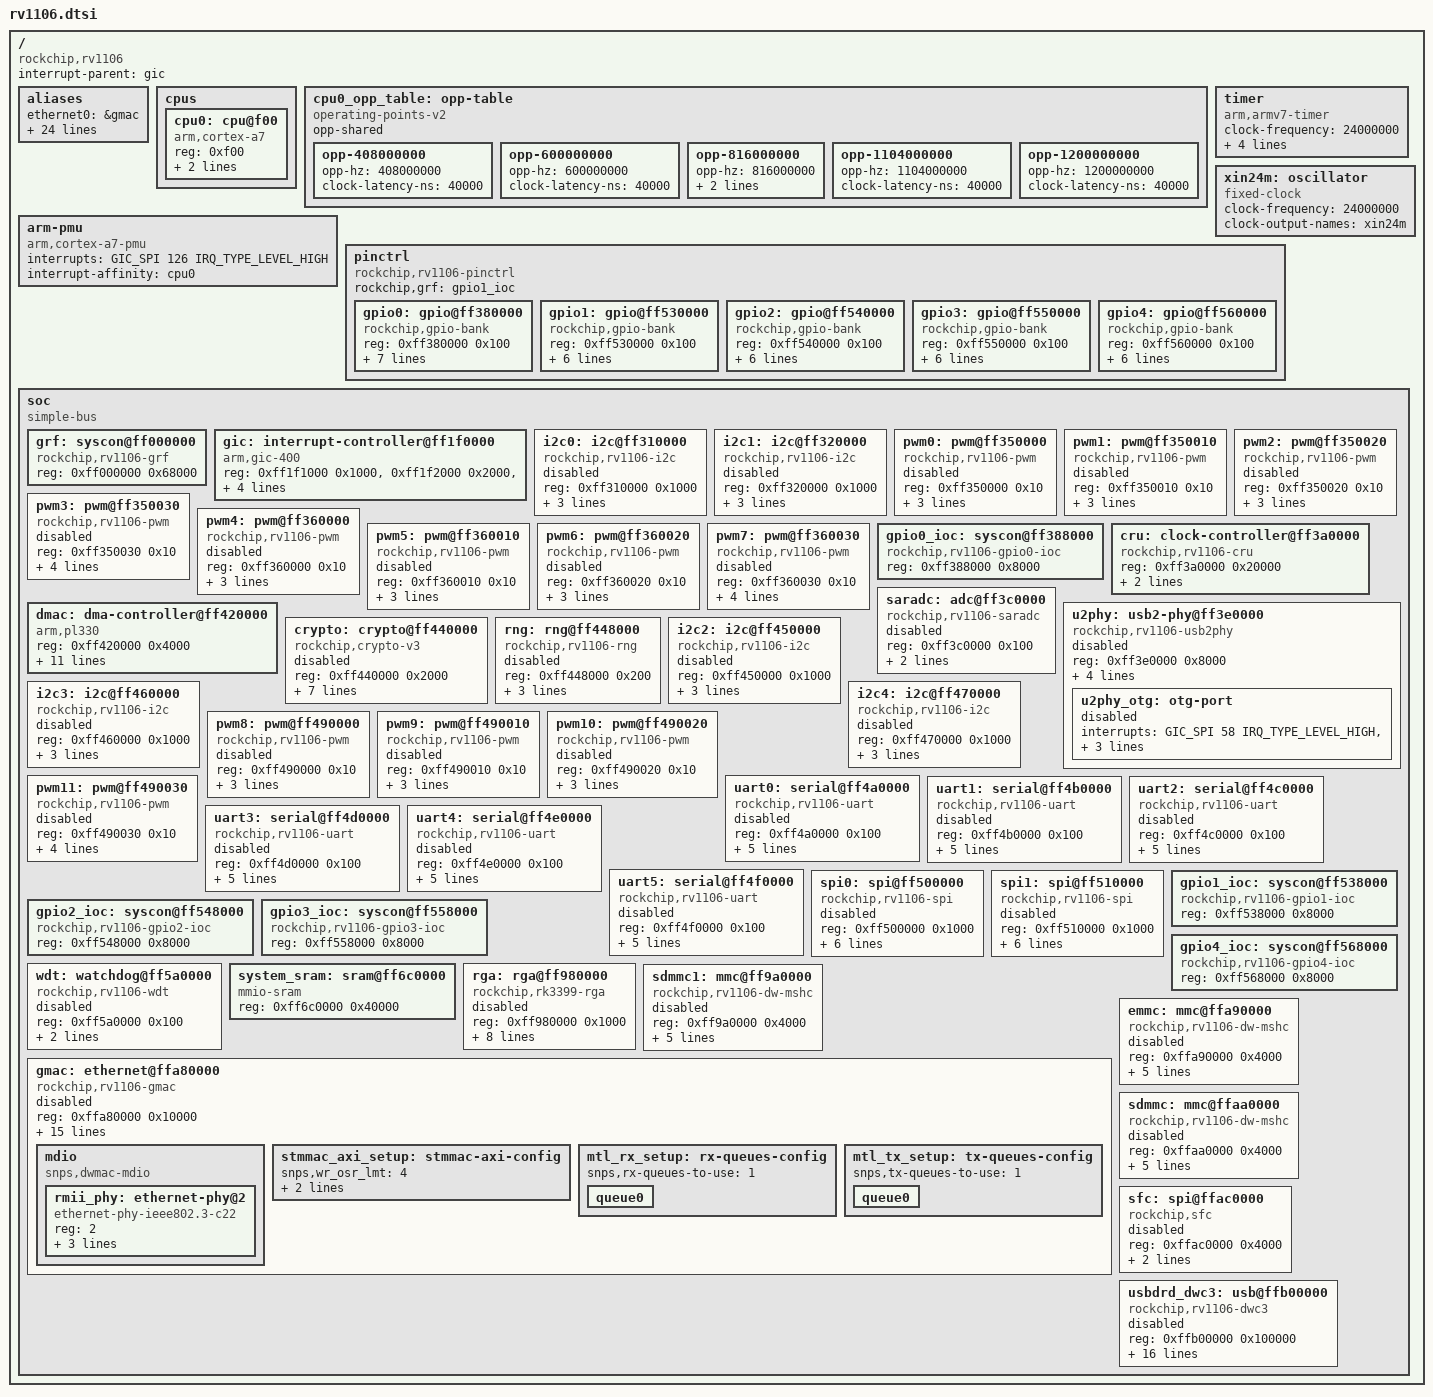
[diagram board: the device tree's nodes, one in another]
// SPDX-License-Identifier: (GPL-2.0+ OR MIT)
/*
 * Copyright (c) 2022 Rockchip Electronics Co., Ltd.
 */

#include <dt-bindings/clock/rockchip,rv1106-cru.h>
#include <dt-bindings/reset/rockchip,rv1106-cru.h>
#include <dt-bindings/gpio/gpio.h>
#include <dt-bindings/interrupt-controller/arm-gic.h>
#include <dt-bindings/interrupt-controller/irq.h>
#include <dt-bindings/pinctrl/rockchip.h>

/ {
	#address-cells = <1>;
	#size-cells = <1>;

	compatible = "rockchip,rv1106";

	interrupt-parent = <&gic>;

	aliases {
		ethernet0 = &gmac;
		gpio0 = &gpio0;
		gpio1 = &gpio1;
		gpio2 = &gpio2;
		gpio3 = &gpio3;
		gpio4 = &gpio4;
		i2c0 = &i2c0;
		i2c1 = &i2c1;
		i2c2 = &i2c2;
		i2c3 = &i2c3;
		i2c4 = &i2c4;
		pwm0 = &pwm0;
		pwm1 = &pwm1;
		pwm2 = &pwm2;
		pwm3 = &pwm3;
		pwm4 = &pwm4;
		pwm5 = &pwm5;
		pwm6 = &pwm6;
		pwm7 = &pwm7;
		pwm8 = &pwm8;
		pwm9 = &pwm9;
		pwm10 = &pwm10;
		pwm11 = &pwm11;
		spi0 = &spi0;
		spi1 = &spi1;
	};

	cpus {
		#address-cells = <1>;
		#size-cells = <0>;

		cpu0: cpu@f00 {
			device_type = "cpu";
			compatible = "arm,cortex-a7";
			reg = <0xf00>;
			clocks = <&cru ARMCLK>;
			operating-points-v2 = <&cpu0_opp_table>;
		};
	};

	/*
	 * Clock-only OPPs (no vdd_cpu). 1.2 GHz muxes to cpu_pvtpll; 816
	 * and below stay on APLL. Do not assigned-clocks ARMCLK to 1.2G.
	 */
	cpu0_opp_table: opp-table {
		compatible = "operating-points-v2";
		opp-shared;

		opp-408000000 {
			opp-hz = /bits/ 64 <408000000>;
			clock-latency-ns = <40000>;
		};
		opp-600000000 {
			opp-hz = /bits/ 64 <600000000>;
			clock-latency-ns = <40000>;
		};
		opp-816000000 {
			opp-hz = /bits/ 64 <816000000>;
			clock-latency-ns = <40000>;
			opp-suspend;
		};
		opp-1104000000 {
			opp-hz = /bits/ 64 <1104000000>;
			clock-latency-ns = <40000>;
		};
		opp-1200000000 {
			opp-hz = /bits/ 64 <1200000000>;
			clock-latency-ns = <40000>;
		};
	};

	arm-pmu {
		compatible = "arm,cortex-a7-pmu";
		interrupts = <GIC_SPI 126 IRQ_TYPE_LEVEL_HIGH>;
		interrupt-affinity = <&cpu0>;
	};

	timer {
		compatible = "arm,armv7-timer";
		clock-frequency = <24000000>;
		interrupts = <GIC_PPI 13 (GIC_CPU_MASK_SIMPLE(1) | IRQ_TYPE_LEVEL_HIGH)>,
			     <GIC_PPI 14 (GIC_CPU_MASK_SIMPLE(1) | IRQ_TYPE_LEVEL_HIGH)>;
		arm,cpu-registers-not-fw-configured;
	};

	xin24m: oscillator {
		compatible = "fixed-clock";
		clock-frequency = <24000000>;
		clock-output-names = "xin24m";
		#clock-cells = <0>;
	};

	pinctrl: pinctrl {
		compatible = "rockchip,rv1106-pinctrl";
		rockchip,grf = <&gpio1_ioc>;
		#address-cells = <1>;
		#size-cells = <1>;
		ranges;

		gpio0: gpio@ff380000 {
			compatible = "rockchip,gpio-bank";
			reg = <0xff380000 0x100>;
			interrupts = <GIC_SPI 5 IRQ_TYPE_LEVEL_HIGH>;
			clocks = <&cru PCLK_PMU_GPIO0>, <&cru DBCLK_PMU_GPIO0>;
			gpio-controller;
			#gpio-cells = <2>;
			gpio-ranges = <&pinctrl 0 0 32>;
			interrupt-controller;
			#interrupt-cells = <2>;
			rockchip,grf = <&gpio0_ioc>;
		};

		gpio1: gpio@ff530000 {
			compatible = "rockchip,gpio-bank";
			reg = <0xff530000 0x100>;
			interrupts = <GIC_SPI 7 IRQ_TYPE_LEVEL_HIGH>;
			clocks = <&cru PCLK_GPIO1>, <&cru DBCLK_GPIO1>;
			gpio-controller;
			#gpio-cells = <2>;
			gpio-ranges = <&pinctrl 0 32 32>;
			interrupt-controller;
			#interrupt-cells = <2>;
			rockchip,grf = <&gpio1_ioc>;
		};

		gpio2: gpio@ff540000 {
			compatible = "rockchip,gpio-bank";
			reg = <0xff540000 0x100>;
			interrupts = <GIC_SPI 9 IRQ_TYPE_LEVEL_HIGH>;
			clocks = <&cru PCLK_GPIO2>, <&cru DBCLK_GPIO2>;
			gpio-controller;
			#gpio-cells = <2>;
			gpio-ranges = <&pinctrl 0 64 32>;
			interrupt-controller;
			#interrupt-cells = <2>;
			rockchip,grf = <&gpio2_ioc>;
		};

		gpio3: gpio@ff550000 {
			compatible = "rockchip,gpio-bank";
			reg = <0xff550000 0x100>;
			interrupts = <GIC_SPI 11 IRQ_TYPE_LEVEL_HIGH>;
			clocks = <&cru PCLK_GPIO3>, <&cru DBCLK_GPIO3>;
			gpio-controller;
			#gpio-cells = <2>;
			gpio-ranges = <&pinctrl 0 96 32>;
			interrupt-controller;
			#interrupt-cells = <2>;
			rockchip,grf = <&gpio3_ioc>;
		};

		gpio4: gpio@ff560000 {
			compatible = "rockchip,gpio-bank";
			reg = <0xff560000 0x100>;
			interrupts = <GIC_SPI 13 IRQ_TYPE_LEVEL_HIGH>;
			clocks = <&cru PCLK_GPIO4>, <&cru DBCLK_GPIO4>;
			gpio-controller;
			#gpio-cells = <2>;
			gpio-ranges = <&pinctrl 0 128 24>;
			interrupt-controller;
			#interrupt-cells = <2>;
			rockchip,grf = <&gpio4_ioc>;
		};
	};

	soc: soc {
		compatible = "simple-bus";
		#address-cells = <1>;
		#size-cells = <1>;
		ranges;

		grf: syscon@ff000000 {
			compatible = "rockchip,rv1106-grf", "syscon";
			reg = <0xff000000 0x68000>;
		};

		gic: interrupt-controller@ff1f0000 {
			compatible = "arm,gic-400";
			reg = <0xff1f1000 0x1000>,
			      <0xff1f2000 0x2000>,
			      <0xff1f4000 0x2000>,
			      <0xff1f6000 0x2000>;
			interrupts = <GIC_PPI 9 (GIC_CPU_MASK_SIMPLE(1) | IRQ_TYPE_LEVEL_HIGH)>;
			interrupt-controller;
			#interrupt-cells = <3>;
			#address-cells = <0>;
		};

		i2c0: i2c@ff310000 {
			compatible = "rockchip,rv1106-i2c", "rockchip,rk3399-i2c";
			reg = <0xff310000 0x1000>;
			interrupts = <GIC_SPI 18 IRQ_TYPE_LEVEL_HIGH>;
			#address-cells = <1>;
			#size-cells = <0>;
			clocks = <&cru CLK_I2C0>, <&cru PCLK_I2C0>;
			clock-names = "i2c", "pclk";
			pinctrl-names = "default";
			pinctrl-0 = <&i2c0m0_xfer>;
			status = "disabled";
		};

		i2c1: i2c@ff320000 {
			compatible = "rockchip,rv1106-i2c", "rockchip,rk3399-i2c";
			reg = <0xff320000 0x1000>;
			interrupts = <GIC_SPI 19 IRQ_TYPE_LEVEL_HIGH>;
			#address-cells = <1>;
			#size-cells = <0>;
			clocks = <&cru CLK_I2C1>, <&cru PCLK_I2C1>;
			clock-names = "i2c", "pclk";
			pinctrl-names = "default";
			pinctrl-0 = <&i2c1m0_xfer>;
			status = "disabled";
		};

		pwm0: pwm@ff350000 {
			compatible = "rockchip,rv1106-pwm", "rockchip,rk3328-pwm";
			reg = <0xff350000 0x10>;
			interrupts = <GIC_SPI 31 IRQ_TYPE_LEVEL_HIGH>;
			#pwm-cells = <3>;
			pinctrl-names = "default";
			pinctrl-0 = <&pwm0m0_pins>;
			clocks = <&cru CLK_PWM0_PERI>, <&cru PCLK_PWM0_PERI>;
			clock-names = "pwm", "pclk";
			status = "disabled";
		};

		pwm1: pwm@ff350010 {
			compatible = "rockchip,rv1106-pwm", "rockchip,rk3328-pwm";
			reg = <0xff350010 0x10>;
			interrupts = <GIC_SPI 31 IRQ_TYPE_LEVEL_HIGH>;
			#pwm-cells = <3>;
			pinctrl-names = "default";
			pinctrl-0 = <&pwm1m0_pins>;
			clocks = <&cru CLK_PWM0_PERI>, <&cru PCLK_PWM0_PERI>;
			clock-names = "pwm", "pclk";
			status = "disabled";
		};

		pwm2: pwm@ff350020 {
			compatible = "rockchip,rv1106-pwm", "rockchip,rk3328-pwm";
			reg = <0xff350020 0x10>;
			interrupts = <GIC_SPI 31 IRQ_TYPE_LEVEL_HIGH>;
			#pwm-cells = <3>;
			pinctrl-names = "default";
			pinctrl-0 = <&pwm2m0_pins>;
			clocks = <&cru CLK_PWM0_PERI>, <&cru PCLK_PWM0_PERI>;
			clock-names = "pwm", "pclk";
			status = "disabled";
		};

		pwm3: pwm@ff350030 {
			compatible = "rockchip,rv1106-pwm", "rockchip,rk3328-pwm";
			reg = <0xff350030 0x10>;
			interrupts = <GIC_SPI 31 IRQ_TYPE_LEVEL_HIGH>,
					<GIC_SPI 32 IRQ_TYPE_LEVEL_HIGH>;
			#pwm-cells = <3>;
			pinctrl-names = "default";
			pinctrl-0 = <&pwm3m0_pins>;
			clocks = <&cru CLK_PWM0_PERI>, <&cru PCLK_PWM0_PERI>;
			clock-names = "pwm", "pclk";
			status = "disabled";
		};

		pwm4: pwm@ff360000 {
			compatible = "rockchip,rv1106-pwm", "rockchip,rk3328-pwm";
			reg = <0xff360000 0x10>;
			interrupts = <GIC_SPI 33 IRQ_TYPE_LEVEL_HIGH>;
			#pwm-cells = <3>;
			pinctrl-names = "default";
			pinctrl-0 = <&pwm4m0_pins>;
			clocks = <&cru CLK_PWM1_PERI>, <&cru PCLK_PWM1_PERI>;
			clock-names = "pwm", "pclk";
			status = "disabled";
		};

		pwm5: pwm@ff360010 {
			compatible = "rockchip,rv1106-pwm", "rockchip,rk3328-pwm";
			reg = <0xff360010 0x10>;
			interrupts = <GIC_SPI 33 IRQ_TYPE_LEVEL_HIGH>;
			#pwm-cells = <3>;
			pinctrl-names = "default";
			pinctrl-0 = <&pwm5m0_pins>;
			clocks = <&cru CLK_PWM1_PERI>, <&cru PCLK_PWM1_PERI>;
			clock-names = "pwm", "pclk";
			status = "disabled";
		};

		pwm6: pwm@ff360020 {
			compatible = "rockchip,rv1106-pwm", "rockchip,rk3328-pwm";
			reg = <0xff360020 0x10>;
			interrupts = <GIC_SPI 33 IRQ_TYPE_LEVEL_HIGH>;
			#pwm-cells = <3>;
			pinctrl-names = "default";
			pinctrl-0 = <&pwm6m0_pins>;
			clocks = <&cru CLK_PWM1_PERI>, <&cru PCLK_PWM1_PERI>;
			clock-names = "pwm", "pclk";
			status = "disabled";
		};

		pwm7: pwm@ff360030 {
			compatible = "rockchip,rv1106-pwm", "rockchip,rk3328-pwm";
			reg = <0xff360030 0x10>;
			interrupts = <GIC_SPI 33 IRQ_TYPE_LEVEL_HIGH>,
					<GIC_SPI 34 IRQ_TYPE_LEVEL_HIGH>;
			#pwm-cells = <3>;
			pinctrl-names = "default";
			pinctrl-0 = <&pwm7m0_pins>;
			clocks = <&cru CLK_PWM1_PERI>, <&cru PCLK_PWM1_PERI>;
			clock-names = "pwm", "pclk";
			status = "disabled";
		};

		gpio0_ioc: syscon@ff388000 {
			compatible = "rockchip,rv1106-gpio0-ioc", "syscon";
			reg = <0xff388000 0x8000>;
		};

		cru: clock-controller@ff3a0000 {
			compatible = "rockchip,rv1106-cru";
			reg = <0xff3a0000 0x20000>;
			clocks = <&xin24m>;
			clock-names = "xin24m";
			rockchip,grf = <&grf>;
			#clock-cells = <1>;
			#reset-cells = <1>;
		};

		saradc: adc@ff3c0000 {
			compatible = "rockchip,rv1106-saradc", "rockchip,rk3588-saradc";
			reg = <0xff3c0000 0x100>;
			interrupts = <GIC_SPI 62 IRQ_TYPE_LEVEL_HIGH>;
			clocks = <&cru CLK_SARADC>, <&cru PCLK_SARADC>;
			clock-names = "saradc", "apb_pclk";
			#io-channel-cells = <1>;
			status = "disabled";
		};

		u2phy: usb2-phy@ff3e0000 {
			compatible = "rockchip,rv1106-usb2phy";
			reg = <0xff3e0000 0x8000>;
			clocks = <&cru CLK_REF_USBPHY>, <&cru PCLK_USBPHY>;
			clock-names = "phyclk", "pclk";
			resets = <&cru SRST_USBPHY_POR>, <&cru SRST_P_USBPHY>;
			reset-names = "phy", "apb";
			rockchip,usbgrf = <&grf>;
			#clock-cells = <0>;
			clock-output-names = "usb480m_phy";
			status = "disabled";

			u2phy_otg: otg-port {
				interrupts = <GIC_SPI 58 IRQ_TYPE_LEVEL_HIGH>,
						<GIC_SPI 59 IRQ_TYPE_LEVEL_HIGH>,
						<GIC_SPI 60 IRQ_TYPE_LEVEL_HIGH>,
						<GIC_SPI 61 IRQ_TYPE_LEVEL_HIGH>;
				interrupt-names = "otg-bvalid", "otg-id",
						"linestate", "disconnect";
				#phy-cells = <0>;
				status = "disabled";
			};
		};

		dmac: dma-controller@ff420000 {
			compatible = "arm,pl330", "arm,primecell";
			reg = <0xff420000 0x4000>;
			interrupts = <GIC_SPI 63 IRQ_TYPE_LEVEL_HIGH>,
					<GIC_SPI 64 IRQ_TYPE_LEVEL_HIGH>,
					<GIC_SPI 65 IRQ_TYPE_LEVEL_HIGH>,
					<GIC_SPI 66 IRQ_TYPE_LEVEL_HIGH>,
					<GIC_SPI 67 IRQ_TYPE_LEVEL_HIGH>,
					<GIC_SPI 68 IRQ_TYPE_LEVEL_HIGH>,
					<GIC_SPI 69 IRQ_TYPE_LEVEL_HIGH>,
					<GIC_SPI 70 IRQ_TYPE_LEVEL_HIGH>,
					<GIC_SPI 79 IRQ_TYPE_LEVEL_HIGH>;
			#dma-cells = <1>;
			clocks = <&cru ACLK_DMAC>;
			clock-names = "apb_pclk";
			arm,pl330-periph-burst;
		};

		crypto: crypto@ff440000 {
			compatible = "rockchip,crypto-v3";
			reg = <0xff440000 0x2000>;
			interrupts = <GIC_SPI 15 IRQ_TYPE_LEVEL_HIGH>;
			clocks = <&cru ACLK_CRYPTO>, <&cru HCLK_CRYPTO>,
				 <&cru CLK_CORE_CRYPTO>, <&cru CLK_PKA_CRYPTO>;
			clock-names = "aclk", "hclk", "sclk", "pka";
			assigned-clocks = <&cru CLK_CORE_CRYPTO>,
					  <&cru CLK_PKA_CRYPTO>;
			assigned-clock-rates = <200000000>, <200000000>;
			resets = <&cru SRST_CORE_CRYPTO>;
			reset-names = "crypto-rst";
			status = "disabled";
		};

		rng: rng@ff448000 {
			compatible = "rockchip,rv1106-rng", "rockchip,rk3588-rng";
			reg = <0xff448000 0x200>;
			interrupts = <GIC_SPI 17 IRQ_TYPE_LEVEL_HIGH>;
			clocks = <&cru HCLK_TRNG_NS>;
			resets = <&cru SRST_H_TRNG_NS>;
			status = "disabled";
		};

		i2c2: i2c@ff450000 {
			compatible = "rockchip,rv1106-i2c", "rockchip,rk3399-i2c";
			reg = <0xff450000 0x1000>;
			interrupts = <GIC_SPI 20 IRQ_TYPE_LEVEL_HIGH>;
			#address-cells = <1>;
			#size-cells = <0>;
			clocks = <&cru CLK_I2C2>, <&cru PCLK_I2C2>;
			clock-names = "i2c", "pclk";
			pinctrl-names = "default";
			pinctrl-0 = <&i2c2m0_xfer>;
			status = "disabled";
		};

		i2c3: i2c@ff460000 {
			compatible = "rockchip,rv1106-i2c", "rockchip,rk3399-i2c";
			reg = <0xff460000 0x1000>;
			interrupts = <GIC_SPI 21 IRQ_TYPE_LEVEL_HIGH>;
			#address-cells = <1>;
			#size-cells = <0>;
			clocks = <&cru CLK_I2C3>, <&cru PCLK_I2C3>;
			clock-names = "i2c", "pclk";
			pinctrl-names = "default";
			pinctrl-0 = <&i2c3m0_xfer>;
			status = "disabled";
		};

		i2c4: i2c@ff470000 {
			compatible = "rockchip,rv1106-i2c", "rockchip,rk3399-i2c";
			reg = <0xff470000 0x1000>;
			interrupts = <GIC_SPI 22 IRQ_TYPE_LEVEL_HIGH>;
			#address-cells = <1>;
			#size-cells = <0>;
			clocks = <&cru CLK_I2C4>, <&cru PCLK_I2C4>;
			clock-names = "i2c", "pclk";
			pinctrl-names = "default";
			pinctrl-0 = <&i2c4m0_xfer>;
			status = "disabled";
		};

		pwm8: pwm@ff490000 {
			compatible = "rockchip,rv1106-pwm", "rockchip,rk3328-pwm";
			reg = <0xff490000 0x10>;
			interrupts = <GIC_SPI 35 IRQ_TYPE_LEVEL_HIGH>;
			#pwm-cells = <3>;
			pinctrl-names = "default";
			pinctrl-0 = <&pwm8m0_pins>;
			clocks = <&cru CLK_PWM2_PERI>, <&cru PCLK_PWM2_PERI>;
			clock-names = "pwm", "pclk";
			status = "disabled";
		};

		pwm9: pwm@ff490010 {
			compatible = "rockchip,rv1106-pwm", "rockchip,rk3328-pwm";
			reg = <0xff490010 0x10>;
			interrupts = <GIC_SPI 35 IRQ_TYPE_LEVEL_HIGH>;
			#pwm-cells = <3>;
			pinctrl-names = "default";
			pinctrl-0 = <&pwm9m0_pins>;
			clocks = <&cru CLK_PWM2_PERI>, <&cru PCLK_PWM2_PERI>;
			clock-names = "pwm", "pclk";
			status = "disabled";
		};

		pwm10: pwm@ff490020 {
			compatible = "rockchip,rv1106-pwm", "rockchip,rk3328-pwm";
			reg = <0xff490020 0x10>;
			interrupts = <GIC_SPI 35 IRQ_TYPE_LEVEL_HIGH>;
			#pwm-cells = <3>;
			pinctrl-names = "default";
			pinctrl-0 = <&pwm10m0_pins>;
			clocks = <&cru CLK_PWM2_PERI>, <&cru PCLK_PWM2_PERI>;
			clock-names = "pwm", "pclk";
			status = "disabled";
		};

		pwm11: pwm@ff490030 {
			compatible = "rockchip,rv1106-pwm", "rockchip,rk3328-pwm";
			reg = <0xff490030 0x10>;
			interrupts = <GIC_SPI 35 IRQ_TYPE_LEVEL_HIGH>,
					<GIC_SPI 36 IRQ_TYPE_LEVEL_HIGH>;
			#pwm-cells = <3>;
			pinctrl-names = "default";
			pinctrl-0 = <&pwm11m0_pins>;
			clocks = <&cru CLK_PWM2_PERI>, <&cru PCLK_PWM2_PERI>;
			clock-names = "pwm", "pclk";
			status = "disabled";
		};

		uart0: serial@ff4a0000 {
			compatible = "rockchip,rv1106-uart", "snps,dw-apb-uart";
			reg = <0xff4a0000 0x100>;
			interrupts = <GIC_SPI 25 IRQ_TYPE_LEVEL_HIGH>;
			reg-shift = <2>;
			reg-io-width = <4>;
			dmas = <&dmac 7>, <&dmac 6>;
			dma-names = "tx", "rx";
			clocks = <&cru SCLK_UART0>, <&cru PCLK_UART0>;
			clock-names = "baudclk", "apb_pclk";
			status = "disabled";
		};

		uart1: serial@ff4b0000 {
			compatible = "rockchip,rv1106-uart", "snps,dw-apb-uart";
			reg = <0xff4b0000 0x100>;
			interrupts = <GIC_SPI 26 IRQ_TYPE_LEVEL_HIGH>;
			reg-shift = <2>;
			reg-io-width = <4>;
			dmas = <&dmac 9>, <&dmac 8>;
			dma-names = "tx", "rx";
			clocks = <&cru SCLK_UART1>, <&cru PCLK_UART1>;
			clock-names = "baudclk", "apb_pclk";
			status = "disabled";
		};

		uart2: serial@ff4c0000 {
			compatible = "rockchip,rv1106-uart", "snps,dw-apb-uart";
			reg = <0xff4c0000 0x100>;
			interrupts = <GIC_SPI 27 IRQ_TYPE_LEVEL_HIGH>;
			reg-shift = <2>;
			reg-io-width = <4>;
			dmas = <&dmac 11>, <&dmac 10>;
			dma-names = "tx", "rx";
			clocks = <&cru SCLK_UART2>, <&cru PCLK_UART2>;
			clock-names = "baudclk", "apb_pclk";
			status = "disabled";
		};

		uart3: serial@ff4d0000 {
			compatible = "rockchip,rv1106-uart", "snps,dw-apb-uart";
			reg = <0xff4d0000 0x100>;
			interrupts = <GIC_SPI 28 IRQ_TYPE_LEVEL_HIGH>;
			reg-shift = <2>;
			reg-io-width = <4>;
			dmas = <&dmac 13>, <&dmac 12>;
			dma-names = "tx", "rx";
			clocks = <&cru SCLK_UART3>, <&cru PCLK_UART3>;
			clock-names = "baudclk", "apb_pclk";
			status = "disabled";
		};

		uart4: serial@ff4e0000 {
			compatible = "rockchip,rv1106-uart", "snps,dw-apb-uart";
			reg = <0xff4e0000 0x100>;
			interrupts = <GIC_SPI 29 IRQ_TYPE_LEVEL_HIGH>;
			reg-shift = <2>;
			reg-io-width = <4>;
			dmas = <&dmac 15>, <&dmac 14>;
			dma-names = "tx", "rx";
			clocks = <&cru SCLK_UART4>, <&cru PCLK_UART4>;
			clock-names = "baudclk", "apb_pclk";
			status = "disabled";
		};

		uart5: serial@ff4f0000 {
			compatible = "rockchip,rv1106-uart", "snps,dw-apb-uart";
			reg = <0xff4f0000 0x100>;
			interrupts = <GIC_SPI 30 IRQ_TYPE_LEVEL_HIGH>;
			reg-shift = <2>;
			reg-io-width = <4>;
			dmas = <&dmac 17>, <&dmac 16>;
			dma-names = "tx", "rx";
			clocks = <&cru SCLK_UART5>, <&cru PCLK_UART5>;
			clock-names = "baudclk", "apb_pclk";
			status = "disabled";
		};

		spi0: spi@ff500000 {
			compatible = "rockchip,rv1106-spi", "rockchip,rk3066-spi";
			reg = <0xff500000 0x1000>;
			interrupts = <GIC_SPI 23 IRQ_TYPE_LEVEL_HIGH>;
			#address-cells = <1>;
			#size-cells = <0>;
			clocks = <&cru CLK_SPI0>, <&cru PCLK_SPI0>, <&cru SCLK_IN_SPI0>;
			clock-names = "spiclk", "apb_pclk", "sclk_in";
			dmas = <&dmac 1>, <&dmac 0>;
			dma-names = "tx", "rx";
			num-cs = <2>;
			pinctrl-names = "default";
			pinctrl-0 = <&spi0m0_cs0 &spi0m0_cs1 &spi0m0_pins>;
			status = "disabled";
		};

		spi1: spi@ff510000 {
			compatible = "rockchip,rv1106-spi", "rockchip,rk3066-spi";
			reg = <0xff510000 0x1000>;
			interrupts = <GIC_SPI 24 IRQ_TYPE_LEVEL_HIGH>;
			#address-cells = <1>;
			#size-cells = <0>;
			clocks = <&cru CLK_SPI1>, <&cru PCLK_SPI1>, <&cru SCLK_IN_SPI1>;
			clock-names = "spiclk", "apb_pclk", "sclk_in";
			dmas = <&dmac 3>, <&dmac 2>;
			dma-names = "tx", "rx";
			num-cs = <2>;
			pinctrl-names = "default";
			pinctrl-0 = <&spi1m0_cs0 &spi1m0_cs1 &spi1m0_pins>;
			status = "disabled";
		};

		gpio1_ioc: syscon@ff538000 {
			compatible = "rockchip,rv1106-gpio1-ioc", "syscon";
			reg = <0xff538000 0x8000>;
		};

		gpio2_ioc: syscon@ff548000 {
			compatible = "rockchip,rv1106-gpio2-ioc", "syscon";
			reg = <0xff548000 0x8000>;
		};

		gpio3_ioc: syscon@ff558000 {
			compatible = "rockchip,rv1106-gpio3-ioc", "syscon";
			reg = <0xff558000 0x8000>;
		};

		gpio4_ioc: syscon@ff568000 {
			compatible = "rockchip,rv1106-gpio4-ioc", "syscon";
			reg = <0xff568000 0x8000>;
		};

		wdt: watchdog@ff5a0000 {
			compatible = "rockchip,rv1106-wdt", "snps,dw-wdt";
			reg = <0xff5a0000 0x100>;
			interrupts = <GIC_SPI 46 IRQ_TYPE_LEVEL_HIGH>;
			clocks = <&cru TCLK_WDT_NS>, <&cru PCLK_WDT_NS>;
			clock-names = "tclk", "pclk";
			status = "disabled";
		};

		system_sram: sram@ff6c0000 {
			compatible = "mmio-sram";
			reg = <0xff6c0000 0x40000>;
			#address-cells = <1>;
			#size-cells = <1>;
			ranges = <0 0xff6c0000 0x40000>;
		};

		/*
		 * RGA2E. Vendor 5.10 calls it rockchip,rga2_core0. Mainline
		 * V4L2 rga is the rk3288/rk3399 command engine; clock/reset
		 * names match that driver. No IOMMU on this block.
		 */
		rga: rga@ff980000 {
			compatible = "rockchip,rk3399-rga";
			reg = <0xff980000 0x1000>;
			interrupts = <GIC_SPI 87 IRQ_TYPE_LEVEL_HIGH>;
			clocks = <&cru ACLK_RGA2E>, <&cru HCLK_RGA2E>,
				 <&cru CLK_CORE_RGA2E>;
			clock-names = "aclk", "hclk", "sclk";
			resets = <&cru SRST_CORE_RGA2E>, <&cru SRST_A_RGA2E>,
				 <&cru SRST_H_RGA2E>;
			reset-names = "core", "axi", "ahb";
			assigned-clocks = <&cru CLK_CORE_RGA2E>;
			assigned-clock-rates = <400000000>;
			/* librga: IOMMU is NA on RV1106/RV1103 RGA2E. */
			rockchip,no-internal-mmu;
			status = "disabled";
		};

		sdmmc1: mmc@ff9a0000 {
			compatible = "rockchip,rv1106-dw-mshc", "rockchip,rk3288-dw-mshc";
			reg = <0xff9a0000 0x4000>;
			interrupts = <GIC_SPI 49 IRQ_TYPE_LEVEL_HIGH>;
			clocks = <&cru HCLK_SDIO>, <&cru CCLK_SRC_SDIO>,
				<&cru SCLK_SDIO_DRV>, <&cru SCLK_SDIO_SAMPLE>;
			clock-names = "biu", "ciu", "ciu-drive", "ciu-sample";
			fifo-depth = <0x100>;
			max-frequency = <200000000>;
			status = "disabled";
		};

		gmac: ethernet@ffa80000 {
			compatible = "rockchip,rv1106-gmac", "snps,dwmac-4.20a";
			reg = <0xffa80000 0x10000>;
			interrupts = <GIC_SPI 93 IRQ_TYPE_LEVEL_HIGH>,
					<GIC_SPI 96 IRQ_TYPE_LEVEL_HIGH>;
			interrupt-names = "macirq", "eth_wake_irq";
			rockchip,grf = <&grf>;
			clocks = <&cru CLK_GMAC0_TX_50M_O>, <&cru CLK_GMAC0_REF_50M>,
				<&cru ACLK_MAC>, <&cru PCLK_MAC>;
			clock-names = "stmmaceth", "clk_mac_ref",
					"aclk_mac", "pclk_mac";
			resets = <&cru SRST_A_MAC>;
			reset-names = "stmmaceth";

			snps,mixed-burst;
			snps,tso;

			snps,axi-config = <&stmmac_axi_setup>;
			snps,mtl-rx-config = <&mtl_rx_setup>;
			snps,mtl-tx-config = <&mtl_tx_setup>;

			phy-mode = "rmii";
			clock_in_out = "input";
			phy-handle = <&rmii_phy>;

			status = "disabled";

			mdio: mdio {
				compatible = "snps,dwmac-mdio";
				#address-cells = <0x1>;
				#size-cells = <0x0>;
				rmii_phy: ethernet-phy@2 {
					compatible = "ethernet-phy-ieee802.3-c22";
					reg = <2>;
					clocks = <&cru CLK_MACPHY>;
					resets = <&cru SRST_MACPHY>;
					phy-is-integrated;
				};
			};

			stmmac_axi_setup: stmmac-axi-config {
				snps,wr_osr_lmt = <4>;
				snps,rd_osr_lmt = <8>;
				snps,blen = <0 0 0 0 16 8 4>;
			};

			mtl_rx_setup: rx-queues-config {
				snps,rx-queues-to-use = <1>;
				queue0 {
					status = "okay";
				};
			};

			mtl_tx_setup: tx-queues-config {
				snps,tx-queues-to-use = <1>;
				queue0 {
					status = "okay";
				};
			};
		};

		emmc: mmc@ffa90000 {
			compatible = "rockchip,rv1106-dw-mshc", "rockchip,rk3288-dw-mshc";
			reg = <0xffa90000 0x4000>;
			interrupts = <GIC_SPI 48 IRQ_TYPE_LEVEL_HIGH>;
			clocks = <&cru HCLK_EMMC>, <&cru CCLK_SRC_EMMC>,
				 <&cru SCLK_EMMC_DRV>, <&cru SCLK_EMMC_SAMPLE>;
			clock-names = "biu", "ciu", "ciu-drive", "ciu-sample";
			fifo-depth = <0x100>;
			max-frequency = <200000000>;
			status = "disabled";
		};

		sdmmc: mmc@ffaa0000 {
			compatible = "rockchip,rv1106-dw-mshc", "rockchip,rk3288-dw-mshc";
			reg = <0xffaa0000 0x4000>;
			interrupts = <GIC_SPI 52 IRQ_TYPE_LEVEL_HIGH>;
			clocks = <&cru HCLK_SDMMC>, <&cru CCLK_SRC_SDMMC>,
				 <&cru SCLK_SDMMC_DRV>, <&cru SCLK_SDMMC_SAMPLE>;
			clock-names = "biu", "ciu", "ciu-drive", "ciu-sample";
			fifo-depth = <0x100>;
			max-frequency = <200000000>;
			status = "disabled";
		};

		sfc: spi@ffac0000 {
			compatible = "rockchip,sfc";
			reg = <0xffac0000 0x4000>;
			interrupts = <GIC_SPI 53 IRQ_TYPE_LEVEL_HIGH>;
			clocks = <&cru SCLK_SFC>, <&cru HCLK_SFC>;
			clock-names = "clk_sfc", "hclk_sfc";
			#address-cells = <1>;
			#size-cells = <0>;
			status = "disabled";
		};

		usbdrd_dwc3: usb@ffb00000 {
			compatible = "rockchip,rv1106-dwc3", "snps,dwc3";
			reg = <0xffb00000 0x100000>;
			interrupts = <GIC_SPI 54 IRQ_TYPE_LEVEL_HIGH>;
			clocks = <&cru CLK_REF_USBOTG>, <&cru ACLK_USBOTG>,
				<&cru CLK_UTMI_USBOTG>;
			clock-names = "ref_clk", "bus_clk", "utmi";
			resets = <&cru SRST_A_USBOTG>;
			dr_mode = "otg";
			maximum-speed = "high-speed";
			phys = <&u2phy_otg>;
			phy-names = "usb2-phy";
			phy_type = "utmi_wide";
			snps,dis_enblslpm_quirk;
			snps,dis-u2-freeclk-exists-quirk;
			snps,dis_u2_susphy_quirk;
			snps,dis-del-phy-power-chg-quirk;
			snps,dis-tx-ipgap-linecheck-quirk;
			snps,usb2-gadget-lpm-disable;
			snps,usb2-lpm-disable;
			snps,parkmode-disable-hs-quirk;
			status = "disabled";
		};
	};
};

#include "rv1106-pinctrl.dtsi"
#include "rv1106-vicap.dtsi"
#include "rv1106-kmpp.dtsi"
